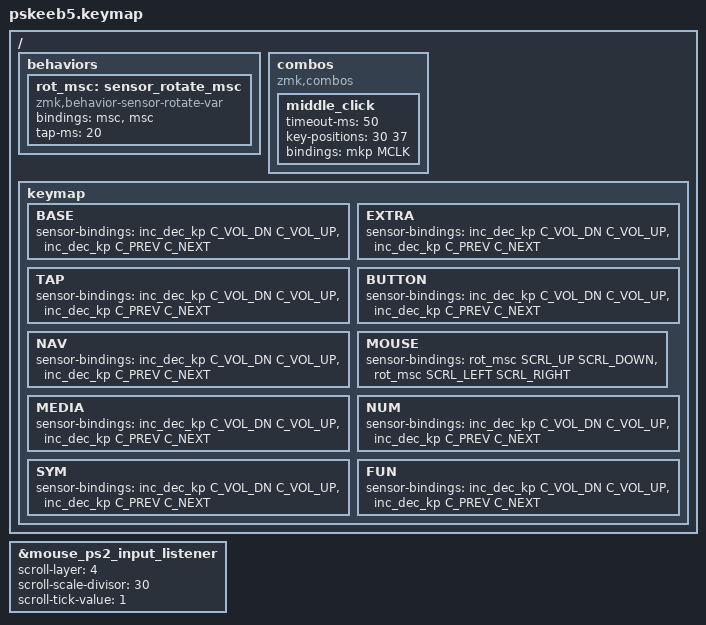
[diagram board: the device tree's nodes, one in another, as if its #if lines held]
// pskeeb5 Miryoku keymap with trackpoint integration

// Trackpoint sensitivity controls (must be before miryoku.h)
#include <behaviors/mouse_setting.dtsi>
#include <dt-bindings/zmk/mouse_settings.h>
#define U_MSS_TP_S_I &mms MS_TP_SENSITIVITY_INCR
#define U_MSS_TP_S_D &mms MS_TP_SENSITIVITY_DECR
// Negative Inertia: extra "kick" given to small/slow movements to overcome
// stick stiction. Too high makes tiny movements overshoot/feel amplified.
#define U_MSS_TP_NI_I &mms MS_TP_NEG_INERTIA_INCR
#define U_MSS_TP_NI_D &mms MS_TP_NEG_INERTIA_DECR
// Value6 / Upper Plateau Speed: the force level at which output speed
// saturates. Too low means full speed is reached with little force.
#define U_MSS_TP_V6_I &mms MS_TP_VALUE6_INCR
#define U_MSS_TP_V6_D &mms MS_TP_VALUE6_DECR

// Miryoku config, mapping, and keymap
#include "miryoku/custom_config.h"
#include "miryoku/mapping/38/pskeeb5.h"
#include "miryoku/miryoku.dtsi"

// Route trackpoint movement to scroll-wheel events while the Nav layer
// (layer 4, see config/miryoku/miryoku_babel/miryoku_layer_list.h) is held,
// instead of moving the cursor. Deliberately NOT the Mouse layer (5): the
// Mouse layer's bottom row has LCLK/RCLK/MCLK, and if trackpoint movement
// scrolled there too, holding a click to drag-select would scroll instead
// of moving the cursor. Keeping scroll on Nav leaves Mouse layer trackpoint
// movement as normal cursor movement, so click-and-drag/select works there,
// while Nav gives a dedicated scroll gesture. The upstream shield default
// (scroll-layer = <3>) targets layer index 3 (BUTTON), which is unrelated.
// MOUSE_PS2_DT_PRESENT is only defined on the right-side (central) build,
// where the trackpoint's mouse_ps2_input_listener node actually exists.
//
// scroll-scale-divisor and scroll-tick-value require our fork of
// kb_zmk_ps2_mouse_trackpoint_driver (see config/west.yml); upstream has
// neither. scroll-tick-value = <1> switches scroll to fixed-step mode: every
// scroll-scale-divisor worth of accumulated movement emits one constant-size
// tick, instead of a value proportional to how hard/fast you pushed. That
// caps top speed at a flat rate (harder push = ticks fire faster, not
// bigger) - proportional mode (tick-value unset) had no such ceiling, which
// is why it still felt too fast at the top end even after the remainder-carry
// fix. scroll-scale-divisor now controls how much movement = one tick.
#ifdef MOUSE_PS2_DT_PRESENT
&mouse_ps2_input_listener {
    scroll-layer = <4>;
    scroll-scale-divisor = <30>;
    scroll-tick-value = <1>;
};
#endif

// Additional behaviors for encoders
/ {
    behaviors {
        rot_msc: sensor_rotate_msc {
            compatible = "zmk,behavior-sensor-rotate-var";
            #sensor-binding-cells = <2>;
            bindings = <&msc>, <&msc>;
            tap-ms = <20>;
        };
    };

    combos {
        compatible = "zmk,combos";
        // Both outer thumb keys (RCLK + LCLK) = middle click
        middle_click {
            timeout-ms = <50>;
            key-positions = <30 37>;
            bindings = <&mkp MCLK>;
        };
    };
};

// Extend Miryoku-generated layers with encoder sensor-bindings.
// DTS overlay merging adds sensor-bindings to the existing layer nodes.
/ {
    keymap {
        BASE {
            sensor-bindings = <&inc_dec_kp C_VOL_DN C_VOL_UP &inc_dec_kp C_PREV C_NEXT>;
        };
        EXTRA {
            sensor-bindings = <&inc_dec_kp C_VOL_DN C_VOL_UP &inc_dec_kp C_PREV C_NEXT>;
        };
        TAP {
            sensor-bindings = <&inc_dec_kp C_VOL_DN C_VOL_UP &inc_dec_kp C_PREV C_NEXT>;
        };
        BUTTON {
            sensor-bindings = <&inc_dec_kp C_VOL_DN C_VOL_UP &inc_dec_kp C_PREV C_NEXT>;
        };
        NAV {
            sensor-bindings = <&inc_dec_kp C_VOL_DN C_VOL_UP &inc_dec_kp C_PREV C_NEXT>;
        };
        MOUSE {
            sensor-bindings = <&rot_msc SCRL_UP SCRL_DOWN &rot_msc SCRL_LEFT SCRL_RIGHT>;
        };
        MEDIA {
            sensor-bindings = <&inc_dec_kp C_VOL_DN C_VOL_UP &inc_dec_kp C_PREV C_NEXT>;
        };
        NUM {
            sensor-bindings = <&inc_dec_kp C_VOL_DN C_VOL_UP &inc_dec_kp C_PREV C_NEXT>;
        };
        SYM {
            sensor-bindings = <&inc_dec_kp C_VOL_DN C_VOL_UP &inc_dec_kp C_PREV C_NEXT>;
        };
        FUN {
            sensor-bindings = <&inc_dec_kp C_VOL_DN C_VOL_UP &inc_dec_kp C_PREV C_NEXT>;
        };
    };
};
